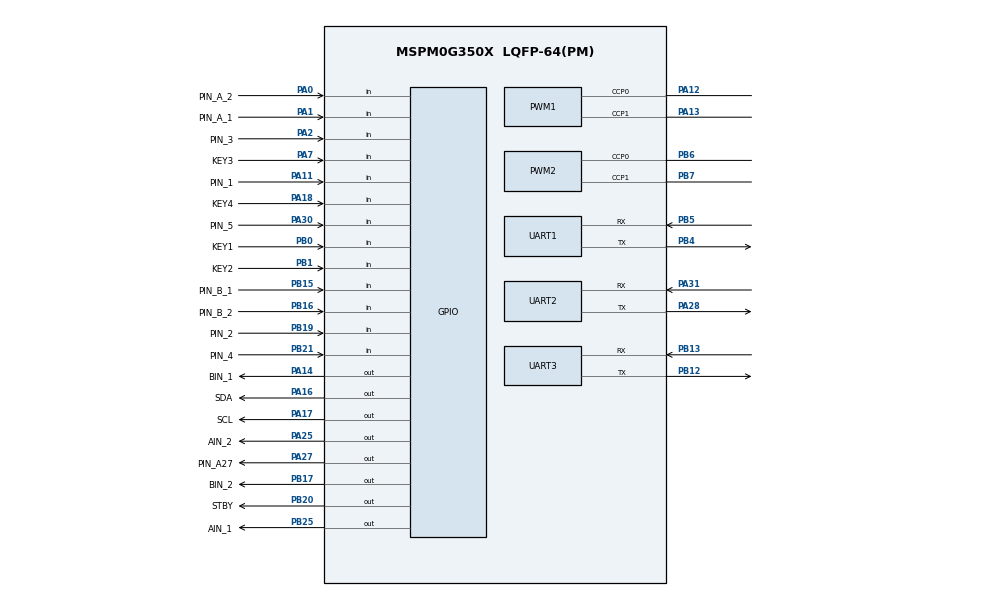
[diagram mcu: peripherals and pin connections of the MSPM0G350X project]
/**
 * @cliArgs --device "MSPM0G350X" --part "Default" --package "LQFP-64(PM)" --product "mspm0_sdk@2.05.01.00"
 * @versions {"tool":"1.24.1+4189"}
 */

/**
 * Import the modules used in this configuration.
 */
const GPIO    = scripting.addModule("/ti/driverlib/GPIO", {}, false);
const GPIO1   = GPIO.addInstance();
const GPIO2   = GPIO.addInstance();
const GPIO3   = GPIO.addInstance();
const GPIO4   = GPIO.addInstance();
const GPIO5   = GPIO.addInstance();
const GPIO6   = GPIO.addInstance();
const GPIO7   = GPIO.addInstance();
const GPIO8   = GPIO.addInstance();
const PWM     = scripting.addModule("/ti/driverlib/PWM", {}, false);
const PWM1    = PWM.addInstance();
const PWM2    = PWM.addInstance();
const SYSCTL  = scripting.addModule("/ti/driverlib/SYSCTL");
const SYSTICK = scripting.addModule("/ti/driverlib/SYSTICK");
const TIMER   = scripting.addModule("/ti/driverlib/TIMER", {}, false);
const TIMER1  = TIMER.addInstance();
const TIMER2  = TIMER.addInstance();
const UART    = scripting.addModule("/ti/driverlib/UART", {}, false);
const UART1   = UART.addInstance();
const UART2   = UART.addInstance();
const UART3   = UART.addInstance();

/**
 * Write custom configuration values to the imported modules.
 */
const gate7  = system.clockTree["MFCLKGATE"];
gate7.enable = true;

GPIO1.$name                          = "GPIO_LED";
GPIO1.associatedPins.create(3);
GPIO1.associatedPins[0].$name        = "LED1";
GPIO1.associatedPins[0].assignedPort = "PORTA";
GPIO1.associatedPins[0].assignedPin  = "26";
GPIO1.associatedPins[1].$name        = "LED2";
GPIO1.associatedPins[1].assignedPort = "PORTA";
GPIO1.associatedPins[1].assignedPin  = "24";
GPIO1.associatedPins[2].$name        = "LED3";
GPIO1.associatedPins[2].assignedPort = "PORTB";
GPIO1.associatedPins[2].assignedPin  = "24";

const Board = scripting.addModule("/ti/driverlib/Board", {}, false);

GPIO2.$name                          = "GPIO_KEY";
GPIO2.associatedPins.create(4);
GPIO2.associatedPins[0].$name        = "KEY1";
GPIO2.associatedPins[0].direction    = "INPUT";
GPIO2.associatedPins[0].assignedPort = "PORTB";
GPIO2.associatedPins[0].assignedPin  = "0";
GPIO2.associatedPins[0].pin.$assign  = "PB0";
GPIO2.associatedPins[1].$name        = "KEY2";
GPIO2.associatedPins[1].direction    = "INPUT";
GPIO2.associatedPins[1].assignedPort = "PORTB";
GPIO2.associatedPins[1].assignedPin  = "1";
GPIO2.associatedPins[1].pin.$assign  = "PB1";
GPIO2.associatedPins[2].$name        = "KEY3";
GPIO2.associatedPins[2].direction    = "INPUT";
GPIO2.associatedPins[2].assignedPort = "PORTA";
GPIO2.associatedPins[2].assignedPin  = "7";
GPIO2.associatedPins[2].pin.$assign  = "PA7";
GPIO2.associatedPins[3].$name        = "KEY4";
GPIO2.associatedPins[3].direction    = "INPUT";
GPIO2.associatedPins[3].assignedPort = "PORTA";
GPIO2.associatedPins[3].assignedPin  = "18";
GPIO2.associatedPins[3].pin.$assign  = "PA18";

GPIO3.$name                          = "GPIO_Buzzer";
GPIO3.associatedPins[0].$name        = "PIN_A27";
GPIO3.associatedPins[0].assignedPort = "PORTA";
GPIO3.associatedPins[0].assignedPin  = "27";
GPIO3.associatedPins[0].pin.$assign  = "PA27";

GPIO4.$name                          = "GPIO_Gray";
GPIO4.associatedPins.create(5);
GPIO4.associatedPins[0].$name        = "PIN_1";
GPIO4.associatedPins[0].direction    = "INPUT";
GPIO4.associatedPins[0].assignedPort = "PORTA";
GPIO4.associatedPins[0].assignedPin  = "11";
GPIO4.associatedPins[0].pin.$assign  = "PA11";
GPIO4.associatedPins[1].$name        = "PIN_2";
GPIO4.associatedPins[1].direction    = "INPUT";
GPIO4.associatedPins[1].assignedPort = "PORTB";
GPIO4.associatedPins[1].assignedPin  = "19";
GPIO4.associatedPins[1].pin.$assign  = "PB19";
GPIO4.associatedPins[2].$name        = "PIN_3";
GPIO4.associatedPins[2].direction    = "INPUT";
GPIO4.associatedPins[2].assignedPort = "PORTA";
GPIO4.associatedPins[2].assignedPin  = "2";
GPIO4.associatedPins[2].pin.$assign  = "PA2";
GPIO4.associatedPins[3].$name        = "PIN_4";
GPIO4.associatedPins[3].direction    = "INPUT";
GPIO4.associatedPins[3].assignedPort = "PORTB";
GPIO4.associatedPins[3].assignedPin  = "21";
GPIO4.associatedPins[3].pin.$assign  = "PB21";
GPIO4.associatedPins[4].$name        = "PIN_5";
GPIO4.associatedPins[4].direction    = "INPUT";
GPIO4.associatedPins[4].assignedPort = "PORTA";
GPIO4.associatedPins[4].assignedPin  = "30";
GPIO4.associatedPins[4].pin.$assign  = "PA30";

GPIO5.$name                          = "GPIO_MOTOR_DIR";
GPIO5.associatedPins.create(5);
GPIO5.associatedPins[0].$name        = "AIN_2";
GPIO5.associatedPins[0].assignedPort = "PORTA";
GPIO5.associatedPins[0].assignedPin  = "25";
GPIO5.associatedPins[0].pin.$assign  = "PA25";
GPIO5.associatedPins[1].$name        = "AIN_1";
GPIO5.associatedPins[1].assignedPin  = "25";
GPIO5.associatedPins[1].assignedPort = "PORTB";
GPIO5.associatedPins[1].pin.$assign  = "PB25";
GPIO5.associatedPins[2].$name        = "STBY";
GPIO5.associatedPins[2].assignedPort = "PORTB";
GPIO5.associatedPins[2].assignedPin  = "20";
GPIO5.associatedPins[2].pin.$assign  = "PB20";
GPIO5.associatedPins[3].$name        = "BIN_1";
GPIO5.associatedPins[3].assignedPort = "PORTA";
GPIO5.associatedPins[3].assignedPin  = "14";
GPIO5.associatedPins[3].pin.$assign  = "PA14";
GPIO5.associatedPins[4].$name        = "BIN_2";
GPIO5.associatedPins[4].assignedPort = "PORTB";
GPIO5.associatedPins[4].assignedPin  = "17";
GPIO5.associatedPins[4].pin.$assign  = "PB17";

GPIO6.$name                               = "GPIO_ENCODERA";
GPIO6.port                                = "PORTA";
GPIO6.associatedPins.create(2);
GPIO6.associatedPins[0].$name             = "PIN_A_1";
GPIO6.associatedPins[0].direction         = "INPUT";
GPIO6.associatedPins[0].assignedPin       = "1";
GPIO6.associatedPins[0].interruptEn       = true;
GPIO6.associatedPins[0].interruptPriority = "0";
GPIO6.associatedPins[0].polarity          = "RISE";
GPIO6.associatedPins[0].pin.$assign       = "PA1";
GPIO6.associatedPins[1].$name             = "PIN_A_2";
GPIO6.associatedPins[1].direction         = "INPUT";
GPIO6.associatedPins[1].assignedPin       = "0";
GPIO6.associatedPins[1].interruptEn       = true;
GPIO6.associatedPins[1].interruptPriority = "0";
GPIO6.associatedPins[1].polarity          = "RISE";
GPIO6.associatedPins[1].pin.$assign       = "PA0";

GPIO7.$name                               = "GPIO_ENCODERB";
GPIO7.port                                = "PORTB";
GPIO7.associatedPins.create(2);
GPIO7.associatedPins[0].$name             = "PIN_B_1";
GPIO7.associatedPins[0].direction         = "INPUT";
GPIO7.associatedPins[0].assignedPin       = "15";
GPIO7.associatedPins[0].interruptEn       = true;
GPIO7.associatedPins[0].interruptPriority = "0";
GPIO7.associatedPins[0].polarity          = "RISE";
GPIO7.associatedPins[0].pin.$assign       = "PB15";
GPIO7.associatedPins[1].$name             = "PIN_B_2";
GPIO7.associatedPins[1].direction         = "INPUT";
GPIO7.associatedPins[1].assignedPin       = "16";
GPIO7.associatedPins[1].interruptEn       = true;
GPIO7.associatedPins[1].interruptPriority = "0";
GPIO7.associatedPins[1].polarity          = "RISE";
GPIO7.associatedPins[1].pin.$assign       = "PB16";

GPIO8.$name                          = "GPIO_OLED";
GPIO8.associatedPins.create(2);
GPIO8.associatedPins[0].$name        = "SCL";
GPIO8.associatedPins[0].assignedPort = "PORTA";
GPIO8.associatedPins[0].assignedPin  = "17";
GPIO8.associatedPins[0].pin.$assign  = "PA17";
GPIO8.associatedPins[1].$name        = "SDA";
GPIO8.associatedPins[1].assignedPort = "PORTA";
GPIO8.associatedPins[1].assignedPin  = "16";
GPIO8.associatedPins[1].pin.$assign  = "PA16";

PWM1.$name                              = "PWM_MotorL";
PWM1.clockPrescale                      = 4;
PWM1.clockDivider                       = 8;
PWM1.timerCount                         = 100;
PWM1.timerStartTimer                    = true;
PWM1.peripheral.ccp0Pin.$assign         = "PA12";
PWM1.peripheral.ccp1Pin.$assign         = "PA13";
PWM1.PWM_CHANNEL_0.$name                = "ti_driverlib_pwm_PWMTimerCC0";
PWM1.PWM_CHANNEL_1.$name                = "ti_driverlib_pwm_PWMTimerCC1";
PWM1.ccp0PinConfig.direction            = scripting.forceWrite("OUTPUT");
PWM1.ccp0PinConfig.hideOutputInversion  = scripting.forceWrite(false);
PWM1.ccp0PinConfig.onlyInternalResistor = scripting.forceWrite(false);
PWM1.ccp0PinConfig.passedPeripheralType = scripting.forceWrite("Digital");
PWM1.ccp0PinConfig.$name                = "ti_driverlib_gpio_GPIOPinGeneric4";
PWM1.ccp1PinConfig.direction            = scripting.forceWrite("OUTPUT");
PWM1.ccp1PinConfig.hideOutputInversion  = scripting.forceWrite(false);
PWM1.ccp1PinConfig.onlyInternalResistor = scripting.forceWrite(false);
PWM1.ccp1PinConfig.passedPeripheralType = scripting.forceWrite("Digital");
PWM1.ccp1PinConfig.$name                = "ti_driverlib_gpio_GPIOPinGeneric5";

PWM2.$name                              = "PWM_MotorR";
PWM2.clockPrescale                      = 4;
PWM2.clockSource                        = "MFCLK";
PWM2.timerCount                         = 100;
PWM2.timerStartTimer                    = true;
PWM2.peripheral.ccp0Pin.$assign         = "PB6";
PWM2.peripheral.ccp1Pin.$assign         = "PB7";
PWM2.PWM_CHANNEL_0.$name                = "ti_driverlib_pwm_PWMTimerCC2";
PWM2.PWM_CHANNEL_1.$name                = "ti_driverlib_pwm_PWMTimerCC3";
PWM2.ccp0PinConfig.direction            = scripting.forceWrite("OUTPUT");
PWM2.ccp0PinConfig.hideOutputInversion  = scripting.forceWrite(false);
PWM2.ccp0PinConfig.onlyInternalResistor = scripting.forceWrite(false);
PWM2.ccp0PinConfig.passedPeripheralType = scripting.forceWrite("Digital");
PWM2.ccp0PinConfig.$name                = "ti_driverlib_gpio_GPIOPinGeneric6";
PWM2.ccp1PinConfig.direction            = scripting.forceWrite("OUTPUT");
PWM2.ccp1PinConfig.hideOutputInversion  = scripting.forceWrite(false);
PWM2.ccp1PinConfig.onlyInternalResistor = scripting.forceWrite(false);
PWM2.ccp1PinConfig.passedPeripheralType = scripting.forceWrite("Digital");
PWM2.ccp1PinConfig.$name                = "ti_driverlib_gpio_GPIOPinGeneric7";

SYSCTL.forceDefaultClkConfig = true;
SYSCTL.clockTreeEn           = true;

SYSTICK.periodEnable      = true;
SYSTICK.period            = 32000;
SYSTICK.interruptEnable   = true;
SYSTICK.systickEnable     = true;
SYSTICK.interruptPriority = "2";

TIMER1.$name              = "TIMER_gimbal";
TIMER1.timerClkDiv        = 8;
TIMER1.timerClkPrescale   = 100;
TIMER1.timerMode          = "PERIODIC";
TIMER1.timerPeriod        = "0.005";
TIMER1.timerStartTimer    = true;
TIMER1.interrupts         = ["ZERO"];
TIMER1.peripheral.$assign = "TIMA1";

TIMER2.timerClkPrescale   = 100;
TIMER2.timerStartTimer    = true;
TIMER2.timerMode          = "PERIODIC";
TIMER2.interrupts         = ["ZERO"];
TIMER2.interruptPriority  = "0";
TIMER2.$name              = "TIMER_classic";
TIMER2.timerPeriod        = "0.005";
TIMER2.peripheral.$assign = "TIMG8";

UART1.$name                            = "UART_1";
UART1.uartClkSrc                       = "MFCLK";
UART1.targetBaudRate                   = 115200;
UART1.enabledInterrupts                = ["RX","TX"];
UART1.peripheral.$assign               = "UART1";
UART1.peripheral.rxPin.$assign         = "PB5";
UART1.peripheral.txPin.$assign         = "PB4";
UART1.txPinConfig.direction            = scripting.forceWrite("OUTPUT");
UART1.txPinConfig.hideOutputInversion  = scripting.forceWrite(false);
UART1.txPinConfig.onlyInternalResistor = scripting.forceWrite(false);
UART1.txPinConfig.passedPeripheralType = scripting.forceWrite("Digital");
UART1.txPinConfig.$name                = "ti_driverlib_gpio_GPIOPinGeneric0";
UART1.rxPinConfig.hideOutputInversion  = scripting.forceWrite(false);
UART1.rxPinConfig.onlyInternalResistor = scripting.forceWrite(false);
UART1.rxPinConfig.passedPeripheralType = scripting.forceWrite("Digital");
UART1.rxPinConfig.$name                = "ti_driverlib_gpio_GPIOPinGeneric1";

UART2.$name                            = "UART_0";
UART2.uartClkSrc                       = "MFCLK";
UART2.targetBaudRate                   = 115200;
UART2.enabledInterrupts                = ["RX","TX"];
UART2.peripheral.rxPin.$assign         = "PA31";
UART2.peripheral.txPin.$assign         = "PA28";
UART2.txPinConfig.direction            = scripting.forceWrite("OUTPUT");
UART2.txPinConfig.hideOutputInversion  = scripting.forceWrite(false);
UART2.txPinConfig.onlyInternalResistor = scripting.forceWrite(false);
UART2.txPinConfig.passedPeripheralType = scripting.forceWrite("Digital");
UART2.txPinConfig.$name                = "ti_driverlib_gpio_GPIOPinGeneric2";
UART2.rxPinConfig.hideOutputInversion  = scripting.forceWrite(false);
UART2.rxPinConfig.onlyInternalResistor = scripting.forceWrite(false);
UART2.rxPinConfig.passedPeripheralType = scripting.forceWrite("Digital");
UART2.rxPinConfig.$name                = "ti_driverlib_gpio_GPIOPinGeneric3";

UART3.$name                    = "UART_2";
UART3.uartClkSrc               = "MFCLK";
UART3.targetBaudRate           = 115200;
UART3.enabledInterrupts        = ["RX","TX"];
UART3.peripheral.rxPin.$assign = "PB13";
UART3.peripheral.txPin.$assign = "PB12";
UART3.txPinConfig.$name        = "ti_driverlib_gpio_GPIOPinGeneric10";
UART3.rxPinConfig.$name        = "ti_driverlib_gpio_GPIOPinGeneric11";

/**
 * Pinmux solution for unlocked pins/peripherals. This ensures that minor changes to the automatic solver in a future
 * version of the tool will not impact the pinmux you originally saw.  These lines can be completely deleted in order to
 * re-solve from scratch.
 */
GPIO1.associatedPins[0].pin.$suggestSolution = "PA26";
GPIO1.associatedPins[1].pin.$suggestSolution = "PA24";
GPIO1.associatedPins[2].pin.$suggestSolution = "PB24";
Board.peripheral.$suggestSolution            = "DEBUGSS";
Board.peripheral.swclkPin.$suggestSolution   = "PA20";
Board.peripheral.swdioPin.$suggestSolution   = "PA19";
PWM1.peripheral.$suggestSolution             = "TIMG0";
PWM2.peripheral.$suggestSolution             = "TIMG6";
UART2.peripheral.$suggestSolution            = "UART0";
UART3.peripheral.$suggestSolution            = "UART3";
